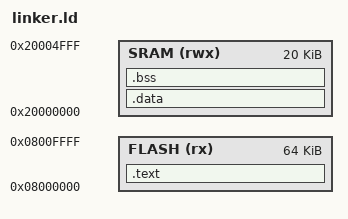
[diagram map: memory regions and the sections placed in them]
ENTRY(Reset_Handler)

MEMORY
{
    FLASH (rx) : ORIGIN = 0x08000000, LENGTH = 64K
    SRAM  (rwx): ORIGIN = 0x20000000, LENGTH = 20K
}

SECTIONS
{
    .text :
    {
        *(.isr_vector)
        *(.text*)
    } > FLASH

    .data : { *(.data*) } > SRAM
    .bss  : { *(.bss*)  } > SRAM
}
